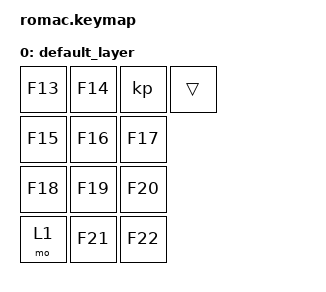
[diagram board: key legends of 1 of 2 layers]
/*
 * Copyright (c) 2020 The ZMK Contributors
 *
 * SPDX-License-Identifier: MIT
 */

#include <behaviors.dtsi>
#include <dt-bindings/zmk/keys.h>
#include <dt-bindings/zmk/ext_power.h>

/ {
    keymap {
        compatible = "zmk,keymap";

        default_layer {
// -------------------
// | F13    | F14 |  _   |
// | F15    | F16 |  F17 |
// | F18    | F19 |  F20 |
// | MO(1)  | F21 |  F22 |
// ----------------------
            bindings = <
    &kp F13 &kp F14 &kp &trans
    &kp F15 &kp F16 &kp F17
    &kp F18 &kp F19 &kp F20
    &mo 1   &kp F21 &kp F22
            >;
        };

        nav_layer {
// -----------------------
// | F23   |  F24   |  _     |
// | PRV   |  PP    |  NXT   |
// | VOLDN |  MUTE  |  VOLUP |
// | _     |  PWR   |  TOG   |
// -----------------------
            bindings = <
    &kp F23      &kp F24     &trans
    &kp C_PREV   &kp C_PP    &kp C_NEXT
    &kp C_VOL_DN &kp K_MUTE  &kp C_VOL_UP
    &trans       &kp K_PWR   &ext_power EP_TOG
            >;
        };
    };
};

